# Port_5_6_4 register map
Vendor: Texas Instruments
Peripheral module from a debugger description file (folder msp430).
Registers are 8-bit, read-write, reset 0x0 unless marked. A register's access mark holds for its fields unless they carry their own. Offsets are as the file gives them; lines under a group give offsets from that group; [hi:lo] are bit positions; {n}, {i} and the like mark numbered series; 'fields as' and 'values as' point back to an identical list; <NAME> marks a mode.

## Port_5/6
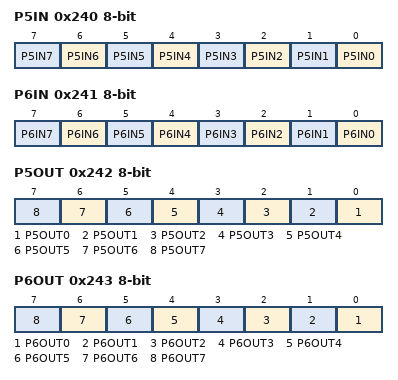
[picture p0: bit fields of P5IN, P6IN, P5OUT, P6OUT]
0x240 P5IN — Port 5 Input
  [n] P5IN{n} (n=0..7)
0x241 P6IN — Port 6 Input
  [n] P6IN{n} (n=0..7)
0x242 P5OUT — Port 5 Output
  [n] P5OUT{n} (n=0..7)
0x243 P6OUT — Port 6 Output
  [n] P6OUT{n} (n=0..7)
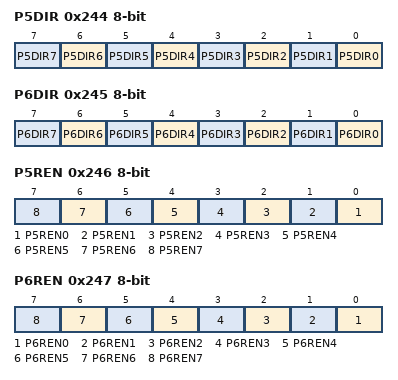
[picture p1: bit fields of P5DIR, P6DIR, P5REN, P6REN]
0x244 P5DIR — Port 5 Direction
  [n] P5DIR{n} (n=0..7)
0x245 P6DIR — Port 6 Direction
  [n] P6DIR{n} (n=0..7)
0x246 P5REN — Port 5 Resistor Enable
  [n] P5REN{n} (n=0..7)
0x247 P6REN — Port 6 Resistor Enable
  [n] P6REN{n} (n=0..7)
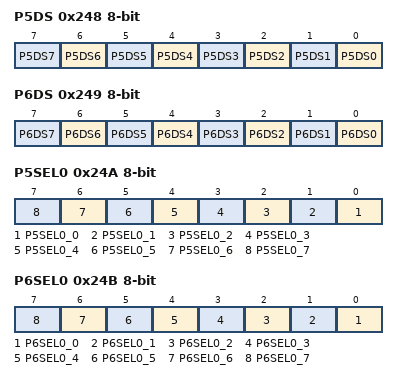
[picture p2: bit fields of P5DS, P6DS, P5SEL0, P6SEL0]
0x248 P5DS — Port 5 Drive Strenght
  [n] P5DS{n} (n=0..7)
0x249 P6DS — Port 6 Drive Strenght
  [n] P6DS{n} (n=0..7)
0x24A P5SEL0 — Port 5 Selection 0
  [n] P5SEL0_{n} (n=0..7)
0x24B P6SEL0 — Port 6 Selection 0
  [n] P6SEL0_{n} (n=0..7)
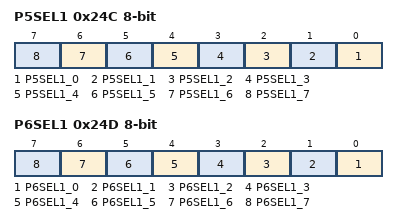
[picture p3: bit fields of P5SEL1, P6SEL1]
0x24C P5SEL1 — Port 5 Selection 1
  [n] P5SEL1_{n} (n=0..7)
0x24D P6SEL1 — Port 6 Selection 1
  [n] P6SEL1_{n} (n=0..7)
